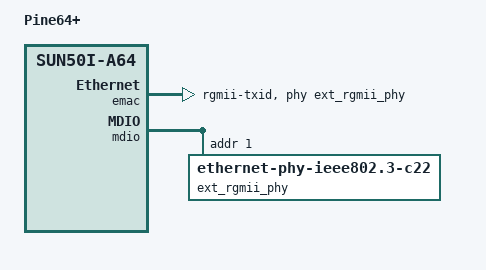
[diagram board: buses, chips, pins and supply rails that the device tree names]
#include "sun50i-a64-pine64.dts"
/ {
	model = "Pine64+";
	compatible = "pine64,pine64-plus", "allwinner,sun50i-a64";
};
&emac {
	pinctrl-names = "default";
	pinctrl-0 = <&rgmii_pins>;
	phy-mode = "rgmii-txid";
	phy-handle = <&ext_rgmii_phy>;
	status = "okay";
};
&mdio {
	ext_rgmii_phy: ethernet-phy@1 {
		compatible = "ethernet-phy-ieee802.3-c22";
		reg = <1>;
	};
};
&reg_dc1sw {
	regulator-enable-ramp-delay = <100000>;
};
